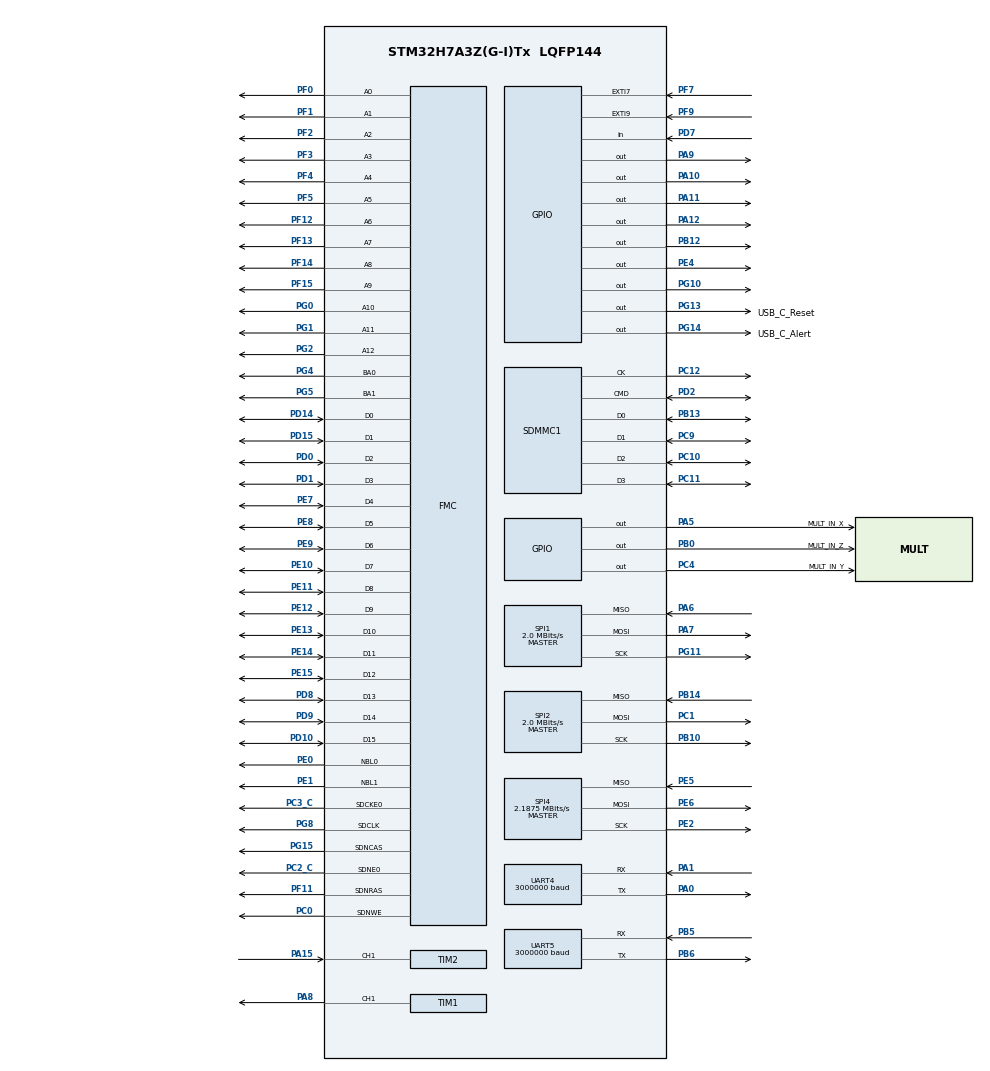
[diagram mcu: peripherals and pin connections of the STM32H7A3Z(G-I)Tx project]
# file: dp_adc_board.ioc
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CORTEX_M7.CPU_DCache=Disabled
CORTEX_M7.CPU_ICache=Disabled
Dma.Request0=SPI4_RX
Dma.Request1=SPI1_RX
Dma.Request2=SPI1_TX
Dma.Request3=SPI2_RX
Dma.Request4=SPI2_TX
Dma.Request5=SPI4_TX
Dma.Request6=UART4_TX
Dma.SPI1_RX.1.Direction=DMA_PERIPH_TO_MEMORY
Dma.SPI1_RX.1.EventEnable=DISABLE
Dma.SPI1_RX.1.FIFOMode=DMA_FIFOMODE_DISABLE
Dma.SPI1_RX.1.Instance=DMA1_Stream0
Dma.SPI1_RX.1.MemDataAlignment=DMA_MDATAALIGN_BYTE
Dma.SPI1_RX.1.MemInc=DMA_MINC_ENABLE
Dma.SPI1_RX.1.Mode=DMA_NORMAL
Dma.SPI1_RX.1.PeriphDataAlignment=DMA_PDATAALIGN_BYTE
Dma.SPI1_RX.1.PeriphInc=DMA_PINC_DISABLE
Dma.SPI1_RX.1.Polarity=HAL_DMAMUX_REQ_GEN_RISING
Dma.SPI1_RX.1.Priority=DMA_PRIORITY_LOW
Dma.SPI1_RX.1.RequestNumber=1
Dma.SPI1_RX.1.SignalID=NONE
Dma.SPI1_RX.1.SyncEnable=DISABLE
Dma.SPI1_RX.1.SyncPolarity=HAL_DMAMUX_SYNC_NO_EVENT
Dma.SPI1_RX.1.SyncRequestNumber=1
Dma.SPI1_RX.1.SyncSignalID=NONE
Dma.SPI1_TX.2.Direction=DMA_MEMORY_TO_PERIPH
Dma.SPI1_TX.2.EventEnable=DISABLE
Dma.SPI1_TX.2.FIFOMode=DMA_FIFOMODE_DISABLE
Dma.SPI1_TX.2.Instance=DMA1_Stream1
Dma.SPI1_TX.2.MemDataAlignment=DMA_MDATAALIGN_BYTE
Dma.SPI1_TX.2.MemInc=DMA_MINC_ENABLE
Dma.SPI1_TX.2.Mode=DMA_NORMAL
Dma.SPI1_TX.2.PeriphDataAlignment=DMA_PDATAALIGN_BYTE
Dma.SPI1_TX.2.PeriphInc=DMA_PINC_DISABLE
Dma.SPI1_TX.2.Polarity=HAL_DMAMUX_REQ_GEN_RISING
Dma.SPI1_TX.2.Priority=DMA_PRIORITY_LOW
Dma.SPI1_TX.2.RequestNumber=1
Dma.SPI1_TX.2.SignalID=NONE
Dma.SPI1_TX.2.SyncEnable=DISABLE
Dma.SPI1_TX.2.SyncPolarity=HAL_DMAMUX_SYNC_NO_EVENT
Dma.SPI1_TX.2.SyncRequestNumber=1
Dma.SPI1_TX.2.SyncSignalID=NONE
Dma.SPI2_RX.3.Direction=DMA_PERIPH_TO_MEMORY
Dma.SPI2_RX.3.EventEnable=DISABLE
Dma.SPI2_RX.3.FIFOMode=DMA_FIFOMODE_DISABLE
Dma.SPI2_RX.3.Instance=DMA1_Stream7
Dma.SPI2_RX.3.MemDataAlignment=DMA_MDATAALIGN_BYTE
Dma.SPI2_RX.3.MemInc=DMA_MINC_ENABLE
Dma.SPI2_RX.3.Mode=DMA_NORMAL
Dma.SPI2_RX.3.PeriphDataAlignment=DMA_PDATAALIGN_BYTE
Dma.SPI2_RX.3.PeriphInc=DMA_PINC_DISABLE
Dma.SPI2_RX.3.Polarity=HAL_DMAMUX_REQ_GEN_RISING
Dma.SPI2_RX.3.Priority=DMA_PRIORITY_LOW
Dma.SPI2_RX.3.RequestNumber=1
Dma.SPI2_RX.3.SignalID=NONE
Dma.SPI2_RX.3.SyncEnable=DISABLE
Dma.SPI2_RX.3.SyncPolarity=HAL_DMAMUX_SYNC_NO_EVENT
Dma.SPI2_RX.3.SyncRequestNumber=1
Dma.SPI2_RX.3.SyncSignalID=NONE
Dma.SPI2_TX.4.Direction=DMA_MEMORY_TO_PERIPH
Dma.SPI2_TX.4.EventEnable=DISABLE
Dma.SPI2_TX.4.FIFOMode=DMA_FIFOMODE_DISABLE
Dma.SPI2_TX.4.Instance=DMA2_Stream0
Dma.SPI2_TX.4.MemDataAlignment=DMA_MDATAALIGN_BYTE
Dma.SPI2_TX.4.MemInc=DMA_MINC_ENABLE
Dma.SPI2_TX.4.Mode=DMA_NORMAL
Dma.SPI2_TX.4.PeriphDataAlignment=DMA_PDATAALIGN_BYTE
Dma.SPI2_TX.4.PeriphInc=DMA_PINC_DISABLE
Dma.SPI2_TX.4.Polarity=HAL_DMAMUX_REQ_GEN_RISING
Dma.SPI2_TX.4.Priority=DMA_PRIORITY_LOW
Dma.SPI2_TX.4.RequestNumber=1
Dma.SPI2_TX.4.SignalID=NONE
Dma.SPI2_TX.4.SyncEnable=DISABLE
Dma.SPI2_TX.4.SyncPolarity=HAL_DMAMUX_SYNC_NO_EVENT
Dma.SPI2_TX.4.SyncRequestNumber=1
Dma.SPI2_TX.4.SyncSignalID=NONE
Dma.SPI4_RX.0.Direction=DMA_PERIPH_TO_MEMORY
Dma.SPI4_RX.0.EventEnable=DISABLE
Dma.SPI4_RX.0.FIFOMode=DMA_FIFOMODE_DISABLE
Dma.SPI4_RX.0.Instance=DMA1_Stream2
Dma.SPI4_RX.0.MemDataAlignment=DMA_MDATAALIGN_BYTE
Dma.SPI4_RX.0.MemInc=DMA_MINC_ENABLE
Dma.SPI4_RX.0.Mode=DMA_NORMAL
Dma.SPI4_RX.0.PeriphDataAlignment=DMA_PDATAALIGN_BYTE
Dma.SPI4_RX.0.PeriphInc=DMA_PINC_DISABLE
Dma.SPI4_RX.0.Polarity=HAL_DMAMUX_REQ_GEN_RISING
Dma.SPI4_RX.0.Priority=DMA_PRIORITY_LOW
Dma.SPI4_RX.0.RequestNumber=1
Dma.SPI4_RX.0.SignalID=NONE
Dma.SPI4_RX.0.SyncEnable=DISABLE
Dma.SPI4_RX.0.SyncPolarity=HAL_DMAMUX_SYNC_NO_EVENT
Dma.SPI4_RX.0.SyncRequestNumber=1
Dma.SPI4_RX.0.SyncSignalID=NONE
Dma.SPI4_TX.5.Direction=DMA_MEMORY_TO_PERIPH
Dma.SPI4_TX.5.EventEnable=DISABLE
Dma.SPI4_TX.5.FIFOMode=DMA_FIFOMODE_DISABLE
Dma.SPI4_TX.5.Instance=DMA1_Stream3
Dma.SPI4_TX.5.MemDataAlignment=DMA_MDATAALIGN_BYTE
Dma.SPI4_TX.5.MemInc=DMA_MINC_ENABLE
Dma.SPI4_TX.5.Mode=DMA_NORMAL
Dma.SPI4_TX.5.PeriphDataAlignment=DMA_PDATAALIGN_BYTE
Dma.SPI4_TX.5.PeriphInc=DMA_PINC_DISABLE
Dma.SPI4_TX.5.Polarity=HAL_DMAMUX_REQ_GEN_RISING
Dma.SPI4_TX.5.Priority=DMA_PRIORITY_LOW
Dma.SPI4_TX.5.RequestNumber=1
Dma.SPI4_TX.5.SignalID=NONE
Dma.SPI4_TX.5.SyncEnable=DISABLE
Dma.SPI4_TX.5.SyncPolarity=HAL_DMAMUX_SYNC_NO_EVENT
Dma.SPI4_TX.5.SyncRequestNumber=1
Dma.SPI4_TX.5.SyncSignalID=NONE
Dma.UART4_TX.6.Direction=DMA_MEMORY_TO_PERIPH
Dma.UART4_TX.6.EventEnable=DISABLE
Dma.UART4_TX.6.FIFOMode=DMA_FIFOMODE_DISABLE
Dma.UART4_TX.6.Instance=DMA1_Stream4
Dma.UART4_TX.6.MemDataAlignment=DMA_MDATAALIGN_BYTE
Dma.UART4_TX.6.MemInc=DMA_MINC_ENABLE
Dma.UART4_TX.6.Mode=DMA_NORMAL
Dma.UART4_TX.6.PeriphDataAlignment=DMA_PDATAALIGN_BYTE
Dma.UART4_TX.6.PeriphInc=DMA_PINC_DISABLE
Dma.UART4_TX.6.Polarity=HAL_DMAMUX_REQ_GEN_RISING
Dma.UART4_TX.6.Priority=DMA_PRIORITY_LOW
Dma.UART4_TX.6.RequestNumber=1
Dma.UART4_TX.6.SignalID=NONE
Dma.UART4_TX.6.SyncEnable=DISABLE
Dma.UART4_TX.6.SyncPolarity=HAL_DMAMUX_SYNC_NO_EVENT
Dma.UART4_TX.6.SyncRequestNumber=1
Dma.UART4_TX.6.SyncSignalID=NONE
FATFS.USE_DMA_CODE_SD=1
FMC.CASLatency1=FMC_SDRAM_CAS_LATENCY_3
FMC.ColumnBitsNumber1=FMC_SDRAM_COLUMN_BITS_NUM_9
FMC.ExitSelfRefreshDelay1=9
FMC.LoadToActiveDelay1=2
FMC.RCDDelay1=3
FMC.RPDelay1=3
FMC.RPDelay2=3
FMC.ReadBurst1=FMC_SDRAM_RBURST_ENABLE
FMC.ReadPipeDelay1=FMC_SDRAM_RPIPE_DELAY_2
FMC.RowCycleDelay1=9
FMC.RowCycleDelay2=9
FMC.SDClockPeriod1=FMC_SDRAM_CLOCK_PERIOD_2
FMC.SelfRefreshTime1=6
FMC.WriteRecoveryTime1=4
Mcu.Family=STM32H7
Mcu.Name=STM32H7A3Z(G-I)Tx
Mcu.Package=LQFP144
NVIC.DMA1_Stream0_IRQn=true\:0\:0\:false\:false\:true\:false\:true\:true
NVIC.DMA1_Stream1_IRQn=true\:0\:0\:false\:false\:true\:false\:true\:true
NVIC.DMA1_Stream2_IRQn=true\:0\:0\:false\:false\:true\:false\:true\:true
NVIC.DMA1_Stream3_IRQn=true\:0\:0\:false\:false\:true\:false\:true\:true
NVIC.DMA1_Stream4_IRQn=true\:0\:0\:false\:false\:true\:false\:true\:true
NVIC.DMA1_Stream7_IRQn=true\:0\:0\:false\:false\:true\:false\:true\:true
NVIC.DMA2_Stream0_IRQn=true\:0\:0\:false\:false\:true\:false\:true\:true
NVIC.PriorityGroup=NVIC_PRIORITYGROUP_4
NVIC.SDMMC1_IRQn=true\:0\:0\:false\:false\:true\:true\:true\:true
NVIC.SPI1_IRQn=true\:0\:0\:false\:false\:true\:true\:true\:true
NVIC.SPI2_IRQn=true\:0\:0\:false\:false\:true\:true\:true\:true
NVIC.SPI4_IRQn=true\:0\:0\:false\:false\:true\:true\:true\:true
NVIC.TIM16_IRQn=true\:0\:0\:false\:false\:true\:true\:true\:true
NVIC.UART4_IRQn=true\:0\:0\:false\:false\:true\:true\:true\:true
NVIC.UART5_IRQn=true\:0\:0\:false\:false\:true\:true\:true\:true
PA0.Mode=Asynchronous
PA0.Signal=UART4_TX
PA1.Mode=Asynchronous
PA1.Signal=UART4_RX
PA10.Signal=GPIO_Output
PA11.Signal=GPIO_Output
PA12.Signal=GPIO_Output
PA13.Mode=Trace_Asynchronous_SW
PA13.Signal=DEBUG_JTMS-SWDIO
PA14.Mode=Trace_Asynchronous_SW
PA14.Signal=DEBUG_JTCK-SWCLK
PA15.Signal=S_TIM2_CH1_ETR
PA5.GPIO_Label=MULT_IN_X
PA5.Signal=GPIO_Output
PA6.Mode=Full_Duplex_Master
PA6.Signal=SPI1_MISO
PA7.Mode=Full_Duplex_Master
PA7.Signal=SPI1_MOSI
PA8.Signal=S_TIM1_CH1
PA9.Signal=GPIO_Output
PB0.GPIO_Label=MULT_IN_Z
PB0.Signal=GPIO_Output
PB10.Mode=Full_Duplex_Master
PB10.Signal=SPI2_SCK
PB12.Signal=GPIO_Output
PB13.Mode=SD_4_bits_Wide_bus
PB13.Signal=SDMMC1_D0
PB14.Mode=Full_Duplex_Master
PB14.Signal=SPI2_MISO
PB3.Mode=Trace_Asynchronous_SW
PB3.Signal=DEBUG_JTDO-SWO
PB5.Mode=Asynchronous
PB5.Signal=UART5_RX
PB6.Mode=Asynchronous
PB6.Signal=UART5_TX
PC0.Signal=FMC_SDNWE
PC1.Mode=Full_Duplex_Master
PC1.Signal=SPI2_MOSI
PC10.Mode=SD_4_bits_Wide_bus
PC10.Signal=SDMMC1_D2
PC11.Mode=SD_4_bits_Wide_bus
PC11.Signal=SDMMC1_D3
PC12.Mode=SD_4_bits_Wide_bus
PC12.Signal=SDMMC1_CK
PC14-OSC32_IN.Mode=LSE-External-Oscillator
PC14-OSC32_IN.Signal=RCC_OSC32_IN
PC15-OSC32_OUT.Mode=LSE-External-Oscillator
PC15-OSC32_OUT.Signal=RCC_OSC32_OUT
PC2_C.Mode=SdramChipSelect1_1
PC2_C.Signal=FMC_SDNE0
PC3_C.Mode=SdramChipSelect1_1
PC3_C.Signal=FMC_SDCKE0
PC4.GPIO_Label=MULT_IN_Y
PC4.Signal=GPIO_Output
PC9.Mode=SD_4_bits_Wide_bus
PC9.Signal=SDMMC1_D1
PD0.Signal=FMC_D2_DA2
PD1.Signal=FMC_D3_DA3
PD10.Signal=FMC_D15_DA15
PD14.Signal=FMC_D0_DA0
PD15.Signal=FMC_D1_DA1
PD2.Mode=SD_4_bits_Wide_bus
PD2.Signal=SDMMC1_CMD
PD7.Signal=GPIO_Input
PD8.Signal=FMC_D13_DA13
PD9.Signal=FMC_D14_DA14
PE0.Signal=FMC_NBL0
PE1.Signal=FMC_NBL1
PE10.Signal=FMC_D7_DA7
PE11.Signal=FMC_D8_DA8
PE12.Signal=FMC_D9_DA9
PE13.Signal=FMC_D10_DA10
PE14.Signal=FMC_D11_DA11
PE15.Signal=FMC_D12_DA12
PE2.Mode=Full_Duplex_Master
PE2.Signal=SPI4_SCK
PE4.Signal=GPIO_Output
PE5.Mode=Full_Duplex_Master
PE5.Signal=SPI4_MISO
PE6.Mode=Full_Duplex_Master
PE6.Signal=SPI4_MOSI
PE7.Signal=FMC_D4_DA4
PE8.Signal=FMC_D5_DA5
PE9.Signal=FMC_D6_DA6
PF0.Signal=FMC_A0
PF1.Signal=FMC_A1
PF11.Signal=FMC_SDNRAS
PF12.Signal=FMC_A6
PF13.Signal=FMC_A7
PF14.Signal=FMC_A8
PF15.Signal=FMC_A9
PF2.Signal=FMC_A2
PF3.Signal=FMC_A3
PF4.Signal=FMC_A4
PF5.Signal=FMC_A5
PF7.GPIO_ModeDefaultEXTI=GPIO_MODE_IT_FALLING
PF7.Signal=GPXTI7
PF9.GPIO_ModeDefaultEXTI=GPIO_MODE_IT_FALLING
PF9.Signal=GPXTI9
PG0.Signal=FMC_A10
PG1.Signal=FMC_A11
PG10.Signal=GPIO_Output
PG11.Mode=Full_Duplex_Master
PG11.Signal=SPI1_SCK
PG13.GPIO_Label=USB_C_Reset
PG13.Signal=GPIO_Output
PG14.GPIO_Label=USB_C_Alert
PG14.Signal=GPIO_Output
PG15.Signal=FMC_SDNCAS
PG2.Signal=FMC_A12
PG4.Signal=FMC_A14_BA0
PG5.Signal=FMC_A15_BA1
PG8.Signal=FMC_SDCLK
PH0-OSC_IN.Mode=HSE-External-Oscillator
PH0-OSC_IN.Signal=RCC_OSC_IN
PH1-OSC_OUT.Mode=HSE-External-Oscillator
PH1-OSC_OUT.Signal=RCC_OSC_OUT
ProjectManager.HeapSize=0x400
ProjectManager.StackSize=0x800
ProjectManager.TargetToolchain=STM32CubeIDE
RCC.ADCFreq_Value=64000000
RCC.APB1Freq_Value=140000000
RCC.APB2Freq_Value=140000000
RCC.APB3Freq_Value=140000000
RCC.APB4Freq_Value=140000000
RCC.CDPPRE=RCC_APB3_DIV2
RCC.CDPPRE1=RCC_APB1_DIV2
RCC.CDPPRE2=RCC_APB2_DIV2
RCC.CortexFreq_Value=280000000
RCC.DIVM1=4
RCC.DIVM2=4
RCC.DIVN1=35
RCC.DIVN2=8
RCC.DIVQ1=1
RCC.FMCCLockSelection=RCC_FMCCLKSOURCE_PLL2
RCC.HCLKFreq_Value=280000000
RCC.HSE_Timout=1000
RCC.HSE_VALUE=24000000
RCC.PLL1_VCO_SEL-AdvancedSettings=RCC_PLL1VCOMEDIUM
RCC.PLL2FRACN=0
RCC.PLL2_VCO_SEL-AdvancedSettings=RCC_PLL2VCOMEDIUM
RCC.PLL3FRACN=0
RCC.PLL3_VCI_Range-AdvancedSettings=RCC_PLL3VCIRANGE_3
RCC.PLLFRACN=0
RCC.PLLSourceVirtual=RCC_PLLSOURCE_HSI
RCC.SDMMC1CLockSelection=RCC_SDMMCCLKSOURCE_PLL2
RCC.SPI123CLockSelection=RCC_SPI123CLKSOURCE_CLKP
RCC.SRDPPRE=RCC_APB4_DIV2
RCC.SYSCLKFreq_VALUE=280000000
RCC.SYSCLKSource=RCC_SYSCLKSOURCE_PLLCLK
RCC.USBFreq_Value=560000000
SDMMC1.ClockDiv=64
SDMMC1.ClockEdge=SDMMC_CLOCK_EDGE_RISING
SH.FMC_A0.0=FMC_A0,13b-sda1
SH.FMC_A1.0=FMC_A1,13b-sda1
SH.FMC_A10.0=FMC_A10,13b-sda1
SH.FMC_A11.0=FMC_A11,13b-sda1
SH.FMC_A12.0=FMC_A12,13b-sda1
SH.FMC_A14_BA0.0=FMC_BA0,FourSdramBanks1
SH.FMC_A15_BA1.0=FMC_BA1,FourSdramBanks1
SH.FMC_A2.0=FMC_A2,13b-sda1
SH.FMC_A3.0=FMC_A3,13b-sda1
SH.FMC_A4.0=FMC_A4,13b-sda1
SH.FMC_A5.0=FMC_A5,13b-sda1
SH.FMC_A6.0=FMC_A6,13b-sda1
SH.FMC_A7.0=FMC_A7,13b-sda1
SH.FMC_A8.0=FMC_A8,13b-sda1
SH.FMC_A9.0=FMC_A9,13b-sda1
SH.FMC_D0_DA0.0=FMC_D0,sd-16b-d1
SH.FMC_D10_DA10.0=FMC_D10,sd-16b-d1
SH.FMC_D11_DA11.0=FMC_D11,sd-16b-d1
SH.FMC_D12_DA12.0=FMC_D12,sd-16b-d1
SH.FMC_D13_DA13.0=FMC_D13,sd-16b-d1
SH.FMC_D14_DA14.0=FMC_D14,sd-16b-d1
SH.FMC_D15_DA15.0=FMC_D15,sd-16b-d1
SH.FMC_D1_DA1.0=FMC_D1,sd-16b-d1
SH.FMC_D2_DA2.0=FMC_D2,sd-16b-d1
SH.FMC_D3_DA3.0=FMC_D3,sd-16b-d1
SH.FMC_D4_DA4.0=FMC_D4,sd-16b-d1
SH.FMC_D5_DA5.0=FMC_D5,sd-16b-d1
SH.FMC_D6_DA6.0=FMC_D6,sd-16b-d1
SH.FMC_D7_DA7.0=FMC_D7,sd-16b-d1
SH.FMC_D8_DA8.0=FMC_D8,sd-16b-d1
SH.FMC_D9_DA9.0=FMC_D9,sd-16b-d1
SH.FMC_NBL0.0=FMC_NBL0,Sd2ByteEnable1
SH.FMC_NBL1.0=FMC_NBL1,Sd2ByteEnable1
SH.FMC_SDCLK.0=FMC_SDCLK,13b-sda1
SH.FMC_SDNCAS.0=FMC_SDNCAS,13b-sda1
SH.FMC_SDNRAS.0=FMC_SDNRAS,13b-sda1
SH.FMC_SDNWE.0=FMC_SDNWE,13b-sda1
SH.S_TIM1_CH1.0=TIM1_CH1,PWM Generation1 CH1
SH.S_TIM2_CH1_ETR.0=TIM2_CH1,Input_Capture1_from_TI1
SPI1.BaudRatePrescaler=SPI_BAUDRATEPRESCALER_32
SPI1.CLKPhase=SPI_PHASE_2EDGE
SPI1.CLKPolarity=SPI_POLARITY_HIGH
SPI1.CalculateBaudRate=2.0 MBits/s
SPI1.DataSize=SPI_DATASIZE_8BIT
SPI1.Direction=SPI_DIRECTION_2LINES
SPI1.Mode=SPI_MODE_MASTER
SPI1.NSSPMode=SPI_NSS_PULSE_DISABLE
SPI1.VirtualType=VM_MASTER
SPI2.BaudRatePrescaler=SPI_BAUDRATEPRESCALER_32
SPI2.CLKPhase=SPI_PHASE_2EDGE
SPI2.CLKPolarity=SPI_POLARITY_HIGH
SPI2.CalculateBaudRate=2.0 MBits/s
SPI2.DataSize=SPI_DATASIZE_8BIT
SPI2.Direction=SPI_DIRECTION_2LINES
SPI2.Mode=SPI_MODE_MASTER
SPI2.NSSPMode=SPI_NSS_PULSE_DISABLE
SPI2.VirtualType=VM_MASTER
SPI4.BaudRatePrescaler=SPI_BAUDRATEPRESCALER_64
SPI4.CLKPhase=SPI_PHASE_2EDGE
SPI4.CLKPolarity=SPI_POLARITY_HIGH
SPI4.CalculateBaudRate=2.1875 MBits/s
SPI4.DataSize=SPI_DATASIZE_8BIT
SPI4.Direction=SPI_DIRECTION_2LINES
SPI4.Mode=SPI_MODE_MASTER
SPI4.NSSPMode=SPI_NSS_PULSE_DISABLE
SPI4.VirtualType=VM_MASTER
TIM1.Channel-PWM\ Generation1\ CH1=TIM_CHANNEL_1
TIM16.Period=10000-1
TIM16.Prescaler=28000-1
TIM2.Channel-Input_Capture1_from_TI1=TIM_CHANNEL_1
TIM2.Prescaler=0
UART4.BaudRate=3000000
UART5.BaudRate=3000000
VP_FATFS_VS_SDIO.Mode=SDIO
VP_TIM16_VS_ClockSourceINT.Mode=Enable_Timer
VP_TIM1_VS_ClockSourceINT.Mode=Internal
VP_TIM2_VS_ClockSourceITR.Mode=TriggerSource_ITR0
VP_TIM2_VS_ControllerModeClock.Mode=Clock Mode
board=custom

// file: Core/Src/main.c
/* USER CODE BEGIN Header */
/**
  ******************************************************************************
  * @file           : main.c
  * @brief          : Main program body
  ******************************************************************************
  * @attention
  *
  * Copyright (c) 2023 STMicroelectronics.
  * All rights reserved.
  *
  * This software is licensed under terms that can be found in the LICENSE file
  * in the root directory of this software component.
  * If no LICENSE file comes with this software, it is provided AS-IS.
  *
  ******************************************************************************
  */
/* USER CODE END Header */
#include "main.h"
#include "fatfs.h"

/* USER CODE BEGIN Includes */
#include <stdio.h>
#include <stdbool.h>
#include "sd_card.h"
#include "fmc_sdram.h"
#include "spi_adc.h"
#include <stdlib.h>
#include <string.h>
/* USER CODE END Includes */

/* USER CODE BEGIN PD */
#define SDRAM_ADD 0xC0000000
#define SDRAM_ADD_INCREMENT 0x27AC40
#define ARRAY_SIZE 12582912
#define SPI_VALUES_TO_CONVERT 5

/* USER CODE END PD */

SD_HandleTypeDef hsd1;

SPI_HandleTypeDef hspi1;
SPI_HandleTypeDef hspi2;
SPI_HandleTypeDef hspi4;
DMA_HandleTypeDef hdma_spi1_rx;
DMA_HandleTypeDef hdma_spi1_tx;
DMA_HandleTypeDef hdma_spi2_rx;
DMA_HandleTypeDef hdma_spi2_tx;
DMA_HandleTypeDef hdma_spi4_rx;
DMA_HandleTypeDef hdma_spi4_tx;

TIM_HandleTypeDef htim1;
TIM_HandleTypeDef htim2;
TIM_HandleTypeDef htim16;

UART_HandleTypeDef huart4;
UART_HandleTypeDef huart5;
DMA_HandleTypeDef hdma_uart4_tx;

SDRAM_HandleTypeDef hsdram1;

/* USER CODE BEGIN PV */
FMC_SDRAM_CommandTypeDef fmc_command;
uint8_t data[1];
uint8_t data2[3];
uint32_t counterSPI1_EXTI = 0;
uint32_t counterSPI2_EXTI = 0;

bool interruptActive = false;

bool flagReset_spi1 = false;
bool flagReset_spi2 = false;
bool flagReset_spi3 = false;
bool sendToSDcard = false;
bool sdCardWriteEnable = false;
bool sdCardInitError = false;
bool sdCardWriteError = false;
bool sdCardOpenFileError = false;

HAL_StatusTypeDef spiStatus[40];
uint8_t pTxData[] = {0x00, 0x00, 0x00, 0x00};
uint8_t adcRawVaues[800]; // 40 x 32bit values
uint32_t tmp_uartCounter = 0;
uint32_t spiValuesBufferCounter = 0;

uint32_t spi1ValuesBufferCounter = 0;
uint32_t spi2ValuesBufferCounter = 0;
uint32_t spi4ValuesBufferCounter = 0;
uint32_t spiCommonBufferCounter = 0;

uint8_t SPS_VALUE_5 = 0x14;
uint8_t SPS_VALUE_20 = 0x11;
uint8_t SPS_VALUE_100 = 0x0E;
uint8_t SPS_VALUE_500 = 0x0B;
uint8_t SPS_VALUE_1000 = 0x0A;

uint8_t spi1Buffer[4] = {0,0,0,0};
uint8_t spi2Buffer[4] = {0,0,0,0};
uint8_t spi4Buffer[4] = {0,0,0,0};

bool spiReadingOngoing;

unsigned long t1 =0;
unsigned long t2 =0;
char fileSpi1Name[] = {'S','P','I','1','.','t','x','t','\0'};
char fileSpi2Name[] = {'S','P','I','2','.','t','x','t','\0'};

uint32_t adcValue_x = 0;
uint32_t adcValue_y = 0;
uint32_t adcValue_z = 0;
uint8_t uartBuffer_x[20];
uint8_t uartBuffer_y[20];
uint8_t uartBuffer_z[20];
int adcLength_x;
int adcLength_x;
int adcLength_x;

uint8_t rxUart4Buffer[1];
uint8_t rxUart5Buffer[1];
uint8_t uartCommand;
bool uartNewCommand = false;

volatile bool enableSPI1Interrupt = false;
bool enableSPI2Interrupt = false;
bool enableSPI4Interrupt = false;

uint32_t spi1ValuesStorage[SDRAM_ADD_INCREMENT] __attribute__((section(".sdram"))) __attribute__((aligned(4)));
uint32_t spi2ValuesStorage[SDRAM_ADD_INCREMENT] __attribute__((section(".sdram"))) __attribute__((aligned(4)));
uint32_t spi4ValuesStorage[SDRAM_ADD_INCREMENT] __attribute__((section(".sdram"))) __attribute__((aligned(4)));

typedef enum {
    red = 0,
    green = 1,
    blue = 2
} colorLED;

char range_x_value = 'H', range_y_value = 'H', range_z_value = 'H';
uint16_t sps = 5;
bool floating_point_values = false, saving_to_sd_card = false;
float gain_x = 0.0f, gain_y = 0.0f, gain_z = 0.0f;
int offset_x = 0, offset_y = 0, offset_z = 0;
bool sending_over_uart = true;

/* USER CODE END PV */

void SystemClock_Config(void);
void PeriphCommonClock_Config(void);
static void MX_GPIO_Init(void);
static void MX_SPI1_Init(void);
static void MX_TIM1_Init(void);
static void MX_UART4_Init(void);
static void MX_FMC_Init(void);
static void MX_SPI2_Init(void);
static void MX_SPI4_Init(void);
static void MX_DMA_Init(void);
static void MX_TIM2_Init(void);
static void MX_SDMMC1_SD_Init(void);
static void MX_TIM16_Init(void);
static void MX_UART5_Init(void);
/* USER CODE BEGIN PFP */
uint32_t findMin(uint32_t a, uint32_t b, uint32_t c);
void setColorLED(colorLED color);
void initialSetupADC(void);
void print_help_uart(void);
/* USER CODE END PFP */

int main(void)
{

  /* MCU Configuration--------------------------------------------------------*/

  /* Reset of all peripherals, Initializes the Flash interface and the Systick. */
  HAL_Init();

  /* Configure the system clock */
  SystemClock_Config();

/* Configure the peripherals common clocks */
  PeriphCommonClock_Config();

  /* USER CODE BEGIN SysInit */
//TODO: need to move DMA init everytime up after GPIO init!!
  /* USER CODE END SysInit */

  /* Initialize all configured peripherals */
  MX_GPIO_Init();
  MX_DMA_Init();
  MX_SPI1_Init();
  MX_TIM1_Init();
  MX_UART4_Init();
  MX_FMC_Init();
  MX_SPI2_Init();
  MX_SPI4_Init();
  MX_TIM2_Init();
  MX_SDMMC1_SD_Init();
  MX_FATFS_Init();
  MX_TIM16_Init();
  MX_UART5_Init();
  /* USER CODE BEGIN 2 */

  // setting up timer for time measuring
  CoreDebug->DEMCR |= CoreDebug_DEMCR_TRCENA_Msk;
  DWT->CYCCNT = 0;
  DWT->CTRL |= DWT_CTRL_CYCCNTENA_Msk;
  HAL_Delay(500);
  /* USER CODE END 2 */

  /* Infinite loop */
  /* USER CODE BEGIN WHILE */
  SDRAM_Startup_Sequence(&hsdram1, &fmc_command);
  sdCardInitError = sd_card_init();
  HAL_Delay(100);

  HAL_NVIC_SetPriority(EXTI9_5_IRQn, 4, 4);
  HAL_NVIC_SetPriority(EXTI15_10_IRQn, 1, 1);
  HAL_NVIC_DisableIRQ(EXTI9_5_IRQn);
  HAL_NVIC_DisableIRQ(EXTI15_10_IRQn);

  // uart4 and uart5 IT enable
  HAL_UART_Receive_IT (&huart4, rxUart4Buffer, 1);
  HAL_UART_Receive_IT (&huart5, rxUart5Buffer, 1);

  // LED timer enable
  HAL_TIM_Base_Start_IT(&htim16);

  if (sdCardInitError == true){
    setColorLED(red);
  }else{
    setColorLED(blue);
    readConfigFile("config.txt");
  }

  spi1_soft_reset();
  spi2_soft_reset();
  spi4_soft_reset();
  spi1_adc_init(SPS_VALUE_5);
  spi2_adc_init(SPS_VALUE_5);
  spi4_adc_init(SPS_VALUE_5);

  //initial setup:
  initialSetupADC();
  HAL_Delay(500);

  __HAL_GPIO_EXTI_CLEAR_IT(GPIO_PIN_5);
  __HAL_GPIO_EXTI_CLEAR_IT(GPIO_PIN_6);
  __HAL_GPIO_EXTI_CLEAR_IT(GPIO_PIN_14);
  HAL_NVIC_EnableIRQ(EXTI9_5_IRQn);
  HAL_NVIC_EnableIRQ(EXTI15_10_IRQn);

  //run all before main loop
  run_all_adc();

  char stringBufferValues[39];

  floating_point_values = true;
    while (1){
      if(spiCommonBufferCounter < findMin(spi1ValuesBufferCounter,spi2ValuesBufferCounter,spi4ValuesBufferCounter)){
        if (floating_point_values == true){
          getStringFromValuesFloat(spi1ValuesStorage[spiCommonBufferCounter],spi2ValuesStorage[spiCommonBufferCounter],spi4ValuesStorage[spiCommonBufferCounter],stringBufferValues, range_x_value, range_y_value, range_z_value);
          if (sending_over_uart ==  true){
            HAL_UART_Transmit(&huart4, stringBufferValues, 33,100);
            HAL_UART_Transmit(&huart5, stringBufferValues, 33,100);
          }
        }else{
          getStringFromValues(spi1ValuesStorage[spiCommonBufferCounter],spi2ValuesStorage[spiCommonBufferCounter],spi4ValuesStorage[spiCommonBufferCounter],stringBufferValues);
          if (sending_over_uart == true){
            HAL_UART_Transmit(&huart4, stringBufferValues, 33,100);
            HAL_UART_Transmit(&huart5, stringBufferValues, 33,100);
          }
        }

        if((sdCardWriteEnable == true) && (sdCardInitError == false) && (sdCardOpenFileError == false)){
          sdCardWriteError = sd_card_write_to_opened_file(stringBufferValues);
          if (sdCardWriteError == true){
            setColorLED(red);
          }else{
            setColorLED(green);
          }
        }
      spiCommonBufferCounter++;
      }

      if (uartNewCommand == true){
        switch (uartCommand) {
          case 'a': // multiplexer X -> 0
            HAL_GPIO_WritePin(GPIOA, GPIO_PIN_5, GPIO_PIN_RESET);
            break;
          case 'b': // multiplexer X -> 1
            HAL_GPIO_WritePin(GPIOA, GPIO_PIN_5, GPIO_PIN_SET);
            break;

          case 'c': // multiplexer Y -> 0
            HAL_GPIO_WritePin(GPIOC, GPIO_PIN_4, GPIO_PIN_RESET);
            break;

          case 'd': // multiplexer Y -> 1
            HAL_GPIO_WritePin(GPIOC, GPIO_PIN_4, GPIO_PIN_SET);
            break;

          case 'e': // multiplexer Z -> 0
            HAL_GPIO_WritePin(GPIOB, GPIO_PIN_0, GPIO_PIN_RESET);
            break;

          case 'f': // multiplexer Z -> 1
            HAL_GPIO_WritePin(GPIOB, GPIO_PIN_0, GPIO_PIN_SET);
            break;

          case 'p':
            floating_point_values = true;
            break;

          case 'r':
            floating_point_values = false;
            break;

          case 's':
            sending_over_uart = true;
            break;

          case 't':
            sending_over_uart = false;
            break;

          case 'h':
          case '?':
            sending_over_uart = false;
            print_help_uart();
            break;

         // Numbers reserved for SPS values
          case '0':
            //set SPS to 5
            setNewSPStoAllADCs(SPS_VALUE_5);
            break;
          case '1':
            //set SPS to 20
            setNewSPStoAllADCs(SPS_VALUE_20);
            break;
          case '2':
            //set SPS to 100
            setNewSPStoAllADCs(SPS_VALUE_100);
            break;
          case '3':
            //set SPS to 500
            setNewSPStoAllADCs(SPS_VALUE_500);
            break;
          case '4':
            //set SPS to 1000
            setNewSPStoAllADCs(SPS_VALUE_1000);
            break;
          default:
            break;
        }
        uartNewCommand = false;
      }
    /* USER CODE END WHILE */

    }
}

void SystemClock_Config(void)
{
  RCC_OscInitTypeDef RCC_OscInitStruct = {0};
  RCC_ClkInitTypeDef RCC_ClkInitStruct = {0};

  /*AXI clock gating */
  RCC->CKGAENR = 0xFFFFFFFF;

  /** Supply configuration update enable
  */
  HAL_PWREx_ConfigSupply(PWR_LDO_SUPPLY);

  /** Configure the main internal regulator output voltage
  */
  __HAL_PWR_VOLTAGESCALING_CONFIG(PWR_REGULATOR_VOLTAGE_SCALE0);

  while(!__HAL_PWR_GET_FLAG(PWR_FLAG_VOSRDY)) {}

  /** Macro to configure the PLL clock source
  */
  __HAL_RCC_PLL_PLLSOURCE_CONFIG(RCC_PLLSOURCE_HSI);

  /** Initializes the RCC Oscillators according to the specified parameters
  * in the RCC_OscInitTypeDef structure.
  */
  RCC_OscInitStruct.OscillatorType = RCC_OSCILLATORTYPE_HSI;
  RCC_OscInitStruct.HSIState = RCC_HSI_DIV1;
  RCC_OscInitStruct.HSICalibrationValue = RCC_HSICALIBRATION_DEFAULT;
  RCC_OscInitStruct.PLL.PLLState = RCC_PLL_ON;
  RCC_OscInitStruct.PLL.PLLSource = RCC_PLLSOURCE_HSI;
  RCC_OscInitStruct.PLL.PLLM = 4;
  RCC_OscInitStruct.PLL.PLLN = 35;
  RCC_OscInitStruct.PLL.PLLP = 2;
  RCC_OscInitStruct.PLL.PLLQ = 1;
  RCC_OscInitStruct.PLL.PLLR = 2;
  RCC_OscInitStruct.PLL.PLLRGE = RCC_PLL1VCIRANGE_3;
  RCC_OscInitStruct.PLL.PLLVCOSEL = RCC_PLL1VCOWIDE;
  RCC_OscInitStruct.PLL.PLLFRACN = 0;
  if (HAL_RCC_OscConfig(&RCC_OscInitStruct) != HAL_OK)
  {
    Error_Handler();
  }

  /** Initializes the CPU, AHB and APB buses clocks
  */
  RCC_ClkInitStruct.ClockType = RCC_CLOCKTYPE_HCLK|RCC_CLOCKTYPE_SYSCLK
                              |RCC_CLOCKTYPE_PCLK1|RCC_CLOCKTYPE_PCLK2
                              |RCC_CLOCKTYPE_D3PCLK1|RCC_CLOCKTYPE_D1PCLK1;
  RCC_ClkInitStruct.SYSCLKSource = RCC_SYSCLKSOURCE_PLLCLK;
  RCC_ClkInitStruct.SYSCLKDivider = RCC_SYSCLK_DIV1;
  RCC_ClkInitStruct.AHBCLKDivider = RCC_HCLK_DIV1;
  RCC_ClkInitStruct.APB3CLKDivider = RCC_APB3_DIV2;
  RCC_ClkInitStruct.APB1CLKDivider = RCC_APB1_DIV2;
  RCC_ClkInitStruct.APB2CLKDivider = RCC_APB2_DIV2;
  RCC_ClkInitStruct.APB4CLKDivider = RCC_APB4_DIV2;

  if (HAL_RCC_ClockConfig(&RCC_ClkInitStruct, FLASH_LATENCY_7) != HAL_OK)
  {
    Error_Handler();
  }
}

void PeriphCommonClock_Config(void)
{
  RCC_PeriphCLKInitTypeDef PeriphClkInitStruct = {0};

  /** Initializes the peripherals clock
  */
  PeriphClkInitStruct.PeriphClockSelection = RCC_PERIPHCLK_FMC|RCC_PERIPHCLK_SDMMC
                              |RCC_PERIPHCLK_CKPER;
  PeriphClkInitStruct.PLL2.PLL2M = 4;
  PeriphClkInitStruct.PLL2.PLL2N = 8;
  PeriphClkInitStruct.PLL2.PLL2P = 2;
  PeriphClkInitStruct.PLL2.PLL2Q = 2;
  PeriphClkInitStruct.PLL2.PLL2R = 2;
  PeriphClkInitStruct.PLL2.PLL2RGE = RCC_PLL2VCIRANGE_3;
  PeriphClkInitStruct.PLL2.PLL2VCOSEL = RCC_PLL2VCOWIDE;
  PeriphClkInitStruct.PLL2.PLL2FRACN = 0;
  PeriphClkInitStruct.FmcClockSelection = RCC_FMCCLKSOURCE_PLL2;
  PeriphClkInitStruct.SdmmcClockSelection = RCC_SDMMCCLKSOURCE_PLL2;
  PeriphClkInitStruct.CkperClockSelection = RCC_CLKPSOURCE_HSI;
  if (HAL_RCCEx_PeriphCLKConfig(&PeriphClkInitStruct) != HAL_OK)
  {
    Error_Handler();
  }
}

static void MX_SDMMC1_SD_Init(void)
{

  hsd1.Instance = SDMMC1;
  hsd1.Init.ClockEdge = SDMMC_CLOCK_EDGE_RISING;
  hsd1.Init.ClockPowerSave = SDMMC_CLOCK_POWER_SAVE_DISABLE;
  hsd1.Init.BusWide = SDMMC_BUS_WIDE_4B;
  hsd1.Init.HardwareFlowControl = SDMMC_HARDWARE_FLOW_CONTROL_DISABLE;
  hsd1.Init.ClockDiv = 64;

}

static void MX_SPI1_Init(void)
{

  /* SPI1 parameter configuration*/
  hspi1.Instance = SPI1;
  hspi1.Init.Mode = SPI_MODE_MASTER;
  hspi1.Init.Direction = SPI_DIRECTION_2LINES;
  hspi1.Init.DataSize = SPI_DATASIZE_8BIT;
  hspi1.Init.CLKPolarity = SPI_POLARITY_HIGH;
  hspi1.Init.CLKPhase = SPI_PHASE_2EDGE;
  hspi1.Init.NSS = SPI_NSS_SOFT;
  hspi1.Init.BaudRatePrescaler = SPI_BAUDRATEPRESCALER_32;
  hspi1.Init.FirstBit = SPI_FIRSTBIT_MSB;
  hspi1.Init.TIMode = SPI_TIMODE_DISABLE;
  hspi1.Init.CRCCalculation = SPI_CRCCALCULATION_DISABLE;
  hspi1.Init.CRCPolynomial = 0x0;
  hspi1.Init.NSSPMode = SPI_NSS_PULSE_DISABLE;
  hspi1.Init.NSSPolarity = SPI_NSS_POLARITY_LOW;
  hspi1.Init.FifoThreshold = SPI_FIFO_THRESHOLD_01DATA;
  hspi1.Init.TxCRCInitializationPattern = SPI_CRC_INITIALIZATION_ALL_ZERO_PATTERN;
  hspi1.Init.RxCRCInitializationPattern = SPI_CRC_INITIALIZATION_ALL_ZERO_PATTERN;
  hspi1.Init.MasterSSIdleness = SPI_MASTER_SS_IDLENESS_00CYCLE;
  hspi1.Init.MasterInterDataIdleness = SPI_MASTER_INTERDATA_IDLENESS_00CYCLE;
  hspi1.Init.MasterReceiverAutoSusp = SPI_MASTER_RX_AUTOSUSP_DISABLE;
  hspi1.Init.MasterKeepIOState = SPI_MASTER_KEEP_IO_STATE_DISABLE;
  hspi1.Init.IOSwap = SPI_IO_SWAP_DISABLE;
  if (HAL_SPI_Init(&hspi1) != HAL_OK)
  {
    Error_Handler();
  }

}

static void MX_SPI2_Init(void)
{

  /* SPI2 parameter configuration*/
  hspi2.Instance = SPI2;
  hspi2.Init.Mode = SPI_MODE_MASTER;
  hspi2.Init.Direction = SPI_DIRECTION_2LINES;
  hspi2.Init.DataSize = SPI_DATASIZE_8BIT;
  hspi2.Init.CLKPolarity = SPI_POLARITY_HIGH;
  hspi2.Init.CLKPhase = SPI_PHASE_2EDGE;
  hspi2.Init.NSS = SPI_NSS_SOFT;
  hspi2.Init.BaudRatePrescaler = SPI_BAUDRATEPRESCALER_32;
  hspi2.Init.FirstBit = SPI_FIRSTBIT_MSB;
  hspi2.Init.TIMode = SPI_TIMODE_DISABLE;
  hspi2.Init.CRCCalculation = SPI_CRCCALCULATION_DISABLE;
  hspi2.Init.CRCPolynomial = 0x0;
  hspi2.Init.NSSPMode = SPI_NSS_PULSE_DISABLE;
  hspi2.Init.NSSPolarity = SPI_NSS_POLARITY_LOW;
  hspi2.Init.FifoThreshold = SPI_FIFO_THRESHOLD_01DATA;
  hspi2.Init.TxCRCInitializationPattern = SPI_CRC_INITIALIZATION_ALL_ZERO_PATTERN;
  hspi2.Init.RxCRCInitializationPattern = SPI_CRC_INITIALIZATION_ALL_ZERO_PATTERN;
  hspi2.Init.MasterSSIdleness = SPI_MASTER_SS_IDLENESS_00CYCLE;
  hspi2.Init.MasterInterDataIdleness = SPI_MASTER_INTERDATA_IDLENESS_00CYCLE;
  hspi2.Init.MasterReceiverAutoSusp = SPI_MASTER_RX_AUTOSUSP_DISABLE;
  hspi2.Init.MasterKeepIOState = SPI_MASTER_KEEP_IO_STATE_DISABLE;
  hspi2.Init.IOSwap = SPI_IO_SWAP_DISABLE;
  if (HAL_SPI_Init(&hspi2) != HAL_OK)
  {
    Error_Handler();
  }

}

static void MX_SPI4_Init(void)
{

  /* SPI4 parameter configuration*/
  hspi4.Instance = SPI4;
  hspi4.Init.Mode = SPI_MODE_MASTER;
  hspi4.Init.Direction = SPI_DIRECTION_2LINES;
  hspi4.Init.DataSize = SPI_DATASIZE_8BIT;
  hspi4.Init.CLKPolarity = SPI_POLARITY_HIGH;
  hspi4.Init.CLKPhase = SPI_PHASE_2EDGE;
  hspi4.Init.NSS = SPI_NSS_SOFT;
  hspi4.Init.BaudRatePrescaler = SPI_BAUDRATEPRESCALER_64;
  hspi4.Init.FirstBit = SPI_FIRSTBIT_MSB;
  hspi4.Init.TIMode = SPI_TIMODE_DISABLE;
  hspi4.Init.CRCCalculation = SPI_CRCCALCULATION_DISABLE;
  hspi4.Init.CRCPolynomial = 0x0;
  hspi4.Init.NSSPMode = SPI_NSS_PULSE_DISABLE;
  hspi4.Init.NSSPolarity = SPI_NSS_POLARITY_LOW;
  hspi4.Init.FifoThreshold = SPI_FIFO_THRESHOLD_01DATA;
  hspi4.Init.TxCRCInitializationPattern = SPI_CRC_INITIALIZATION_ALL_ZERO_PATTERN;
  hspi4.Init.RxCRCInitializationPattern = SPI_CRC_INITIALIZATION_ALL_ZERO_PATTERN;
  hspi4.Init.MasterSSIdleness = SPI_MASTER_SS_IDLENESS_00CYCLE;
  hspi4.Init.MasterInterDataIdleness = SPI_MASTER_INTERDATA_IDLENESS_00CYCLE;
  hspi4.Init.MasterReceiverAutoSusp = SPI_MASTER_RX_AUTOSUSP_DISABLE;
  hspi4.Init.MasterKeepIOState = SPI_MASTER_KEEP_IO_STATE_DISABLE;
  hspi4.Init.IOSwap = SPI_IO_SWAP_DISABLE;
  if (HAL_SPI_Init(&hspi4) != HAL_OK)
  {
    Error_Handler();
  }

}

static void MX_TIM1_Init(void)
{

  TIM_ClockConfigTypeDef sClockSourceConfig = {0};
  TIM_MasterConfigTypeDef sMasterConfig = {0};
  TIM_OC_InitTypeDef sConfigOC = {0};
  TIM_BreakDeadTimeConfigTypeDef sBreakDeadTimeConfig = {0};

  htim1.Instance = TIM1;
  htim1.Init.Prescaler = 0;
  htim1.Init.CounterMode = TIM_COUNTERMODE_UP;
  htim1.Init.Period = 65535;
  htim1.Init.ClockDivision = TIM_CLOCKDIVISION_DIV1;
  htim1.Init.RepetitionCounter = 0;
  htim1.Init.AutoReloadPreload = TIM_AUTORELOAD_PRELOAD_DISABLE;
  if (HAL_TIM_Base_Init(&htim1) != HAL_OK)
  {
    Error_Handler();
  }
  sClockSourceConfig.ClockSource = TIM_CLOCKSOURCE_INTERNAL;
  if (HAL_TIM_ConfigClockSource(&htim1, &sClockSourceConfig) != HAL_OK)
  {
    Error_Handler();
  }
  if (HAL_TIM_PWM_Init(&htim1) != HAL_OK)
  {
    Error_Handler();
  }
  sMasterConfig.MasterOutputTrigger = TIM_TRGO_RESET;
  sMasterConfig.MasterOutputTrigger2 = TIM_TRGO2_RESET;
  sMasterConfig.MasterSlaveMode = TIM_MASTERSLAVEMODE_DISABLE;
  if (HAL_TIMEx_MasterConfigSynchronization(&htim1, &sMasterConfig) != HAL_OK)
  {
    Error_Handler();
  }
  sConfigOC.OCMode = TIM_OCMODE_PWM1;
  sConfigOC.Pulse = 0;
  sConfigOC.OCPolarity = TIM_OCPOLARITY_HIGH;
  sConfigOC.OCNPolarity = TIM_OCNPOLARITY_HIGH;
  sConfigOC.OCFastMode = TIM_OCFAST_DISABLE;
  sConfigOC.OCIdleState = TIM_OCIDLESTATE_RESET;
  sConfigOC.OCNIdleState = TIM_OCNIDLESTATE_RESET;
  if (HAL_TIM_PWM_ConfigChannel(&htim1, &sConfigOC, TIM_CHANNEL_1) != HAL_OK)
  {
    Error_Handler();
  }
  sBreakDeadTimeConfig.OffStateRunMode = TIM_OSSR_DISABLE;
  sBreakDeadTimeConfig.OffStateIDLEMode = TIM_OSSI_DISABLE;
  sBreakDeadTimeConfig.LockLevel = TIM_LOCKLEVEL_OFF;
  sBreakDeadTimeConfig.DeadTime = 0;
  sBreakDeadTimeConfig.BreakState = TIM_BREAK_DISABLE;
  sBreakDeadTimeConfig.BreakPolarity = TIM_BREAKPOLARITY_HIGH;
  sBreakDeadTimeConfig.BreakFilter = 0;
  sBreakDeadTimeConfig.Break2State = TIM_BREAK2_DISABLE;
  sBreakDeadTimeConfig.Break2Polarity = TIM_BREAK2POLARITY_HIGH;
  sBreakDeadTimeConfig.Break2Filter = 0;
  sBreakDeadTimeConfig.AutomaticOutput = TIM_AUTOMATICOUTPUT_DISABLE;
  if (HAL_TIMEx_ConfigBreakDeadTime(&htim1, &sBreakDeadTimeConfig) != HAL_OK)
  {
    Error_Handler();
  }
  HAL_TIM_MspPostInit(&htim1);

}

static void MX_TIM2_Init(void)
{

  TIM_SlaveConfigTypeDef sSlaveConfig = {0};
  TIM_MasterConfigTypeDef sMasterConfig = {0};
  TIM_IC_InitTypeDef sConfigIC = {0};

  htim2.Instance = TIM2;
  htim2.Init.Prescaler = 0;
  htim2.Init.CounterMode = TIM_COUNTERMODE_UP;
  htim2.Init.Period = 4294967295;
  htim2.Init.ClockDivision = TIM_CLOCKDIVISION_DIV1;
  htim2.Init.AutoReloadPreload = TIM_AUTORELOAD_PRELOAD_DISABLE;
  if (HAL_TIM_Base_Init(&htim2) != HAL_OK)
  {
    Error_Handler();
  }
  if (HAL_TIM_IC_Init(&htim2) != HAL_OK)
  {
    Error_Handler();
  }
  sSlaveConfig.SlaveMode = TIM_SLAVEMODE_EXTERNAL1;
  sSlaveConfig.InputTrigger = TIM_TS_ITR0;
  if (HAL_TIM_SlaveConfigSynchro(&htim2, &sSlaveConfig) != HAL_OK)
  {
    Error_Handler();
  }
  sMasterConfig.MasterOutputTrigger = TIM_TRGO_RESET;
  sMasterConfig.MasterSlaveMode = TIM_MASTERSLAVEMODE_DISABLE;
  if (HAL_TIMEx_MasterConfigSynchronization(&htim2, &sMasterConfig) != HAL_OK)
  {
    Error_Handler();
  }
  sConfigIC.ICPolarity = TIM_INPUTCHANNELPOLARITY_RISING;
  sConfigIC.ICSelection = TIM_ICSELECTION_DIRECTTI;
  sConfigIC.ICPrescaler = TIM_ICPSC_DIV1;
  sConfigIC.ICFilter = 0;
  if (HAL_TIM_IC_ConfigChannel(&htim2, &sConfigIC, TIM_CHANNEL_1) != HAL_OK)
  {
    Error_Handler();
  }

}

static void MX_TIM16_Init(void)
{

  htim16.Instance = TIM16;
  htim16.Init.Prescaler = 28000-1;
  htim16.Init.CounterMode = TIM_COUNTERMODE_UP;
  htim16.Init.Period = 10000-1;
  htim16.Init.ClockDivision = TIM_CLOCKDIVISION_DIV1;
  htim16.Init.RepetitionCounter = 0;
  htim16.Init.AutoReloadPreload = TIM_AUTORELOAD_PRELOAD_DISABLE;
  if (HAL_TIM_Base_Init(&htim16) != HAL_OK)
  {
    Error_Handler();
  }

}

static void MX_UART4_Init(void)
{

  huart4.Instance = UART4;
  huart4.Init.BaudRate = 3000000;
  huart4.Init.WordLength = UART_WORDLENGTH_8B;
  huart4.Init.StopBits = UART_STOPBITS_1;
  huart4.Init.Parity = UART_PARITY_NONE;
  huart4.Init.Mode = UART_MODE_TX_RX;
  huart4.Init.HwFlowCtl = UART_HWCONTROL_NONE;
  huart4.Init.OverSampling = UART_OVERSAMPLING_16;
  huart4.Init.OneBitSampling = UART_ONE_BIT_SAMPLE_DISABLE;
  huart4.Init.ClockPrescaler = UART_PRESCALER_DIV1;
  huart4.AdvancedInit.AdvFeatureInit = UART_ADVFEATURE_NO_INIT;
  if (HAL_UART_Init(&huart4) != HAL_OK)
  {
    Error_Handler();
  }
  if (HAL_UARTEx_SetTxFifoThreshold(&huart4, UART_TXFIFO_THRESHOLD_1_8) != HAL_OK)
  {
    Error_Handler();
  }
  if (HAL_UARTEx_SetRxFifoThreshold(&huart4, UART_RXFIFO_THRESHOLD_1_8) != HAL_OK)
  {
    Error_Handler();
  }
  if (HAL_UARTEx_DisableFifoMode(&huart4) != HAL_OK)
  {
    Error_Handler();
  }

}

static void MX_UART5_Init(void)
{

  huart5.Instance = UART5;
  huart5.Init.BaudRate = 3000000;
  huart5.Init.WordLength = UART_WORDLENGTH_8B;
  huart5.Init.StopBits = UART_STOPBITS_1;
  huart5.Init.Parity = UART_PARITY_NONE;
  huart5.Init.Mode = UART_MODE_TX_RX;
  huart5.Init.HwFlowCtl = UART_HWCONTROL_NONE;
  huart5.Init.OverSampling = UART_OVERSAMPLING_16;
  huart5.Init.OneBitSampling = UART_ONE_BIT_SAMPLE_DISABLE;
  huart5.Init.ClockPrescaler = UART_PRESCALER_DIV1;
  huart5.AdvancedInit.AdvFeatureInit = UART_ADVFEATURE_NO_INIT;
  if (HAL_UART_Init(&huart5) != HAL_OK)
  {
    Error_Handler();
  }
  if (HAL_UARTEx_SetTxFifoThreshold(&huart5, UART_TXFIFO_THRESHOLD_1_8) != HAL_OK)
  {
    Error_Handler();
  }
  if (HAL_UARTEx_SetRxFifoThreshold(&huart5, UART_RXFIFO_THRESHOLD_1_8) != HAL_OK)
  {
    Error_Handler();
  }
  if (HAL_UARTEx_DisableFifoMode(&huart5) != HAL_OK)
  {
    Error_Handler();
  }

}

static void MX_DMA_Init(void)
{

  /* DMA controller clock enable */
  __HAL_RCC_DMA1_CLK_ENABLE();
  __HAL_RCC_DMA2_CLK_ENABLE();

  /* DMA interrupt init */
  /* DMA1_Stream0_IRQn interrupt configuration */
  HAL_NVIC_SetPriority(DMA1_Stream0_IRQn, 0, 0);
  HAL_NVIC_EnableIRQ(DMA1_Stream0_IRQn);
  /* DMA1_Stream1_IRQn interrupt configuration */
  HAL_NVIC_SetPriority(DMA1_Stream1_IRQn, 0, 0);
  HAL_NVIC_EnableIRQ(DMA1_Stream1_IRQn);
  /* DMA1_Stream2_IRQn interrupt configuration */
  HAL_NVIC_SetPriority(DMA1_Stream2_IRQn, 0, 0);
  HAL_NVIC_EnableIRQ(DMA1_Stream2_IRQn);
  /* DMA1_Stream3_IRQn interrupt configuration */
  HAL_NVIC_SetPriority(DMA1_Stream3_IRQn, 0, 0);
  HAL_NVIC_EnableIRQ(DMA1_Stream3_IRQn);
  /* DMA1_Stream4_IRQn interrupt configuration */
  HAL_NVIC_SetPriority(DMA1_Stream4_IRQn, 0, 0);
  HAL_NVIC_EnableIRQ(DMA1_Stream4_IRQn);
  /* DMA1_Stream7_IRQn interrupt configuration */
  HAL_NVIC_SetPriority(DMA1_Stream7_IRQn, 0, 0);
  HAL_NVIC_EnableIRQ(DMA1_Stream7_IRQn);
  /* DMA2_Stream0_IRQn interrupt configuration */
  HAL_NVIC_SetPriority(DMA2_Stream0_IRQn, 0, 0);
  HAL_NVIC_EnableIRQ(DMA2_Stream0_IRQn);

}

/* FMC initialization function */
static void MX_FMC_Init(void)
{

  FMC_SDRAM_TimingTypeDef SdramTiming = {0};

  /** Perform the SDRAM1 memory initialization sequence
  */
  hsdram1.Instance = FMC_SDRAM_DEVICE;
  /* hsdram1.Init */
  hsdram1.Init.SDBank = FMC_SDRAM_BANK1;
  hsdram1.Init.ColumnBitsNumber = FMC_SDRAM_COLUMN_BITS_NUM_9;
  hsdram1.Init.RowBitsNumber = FMC_SDRAM_ROW_BITS_NUM_13;
  hsdram1.Init.MemoryDataWidth = FMC_SDRAM_MEM_BUS_WIDTH_16;
  hsdram1.Init.InternalBankNumber = FMC_SDRAM_INTERN_BANKS_NUM_4;
  hsdram1.Init.CASLatency = FMC_SDRAM_CAS_LATENCY_3;
  hsdram1.Init.WriteProtection = FMC_SDRAM_WRITE_PROTECTION_DISABLE;
  hsdram1.Init.SDClockPeriod = FMC_SDRAM_CLOCK_PERIOD_2;
  hsdram1.Init.ReadBurst = FMC_SDRAM_RBURST_ENABLE;
  hsdram1.Init.ReadPipeDelay = FMC_SDRAM_RPIPE_DELAY_2;
  /* SdramTiming */
  SdramTiming.LoadToActiveDelay = 2;
  SdramTiming.ExitSelfRefreshDelay = 9;
  SdramTiming.SelfRefreshTime = 6;
  SdramTiming.RowCycleDelay = 9;
  SdramTiming.WriteRecoveryTime = 4;
  SdramTiming.RPDelay = 3;
  SdramTiming.RCDDelay = 3;

  if (HAL_SDRAM_Init(&hsdram1, &SdramTiming) != HAL_OK)
  {
    Error_Handler( );
  }

}

static void MX_GPIO_Init(void)
{
  GPIO_InitTypeDef GPIO_InitStruct = {0};

  /* GPIO Ports Clock Enable */
  __HAL_RCC_GPIOE_CLK_ENABLE();
  __HAL_RCC_GPIOC_CLK_ENABLE();
  __HAL_RCC_GPIOF_CLK_ENABLE();
  __HAL_RCC_GPIOH_CLK_ENABLE();
  __HAL_RCC_GPIOA_CLK_ENABLE();
  __HAL_RCC_GPIOB_CLK_ENABLE();
  __HAL_RCC_GPIOG_CLK_ENABLE();
  __HAL_RCC_GPIOD_CLK_ENABLE();

  /*Configure GPIO pin Output Level */
  HAL_GPIO_WritePin(GPIOE, GPIO_PIN_4, GPIO_PIN_RESET);

  /*Configure GPIO pin Output Level */
  HAL_GPIO_WritePin(GPIOA, MULT_IN_X_Pin|GPIO_PIN_9|GPIO_PIN_10|GPIO_PIN_11
                          |GPIO_PIN_12, GPIO_PIN_RESET);

  /*Configure GPIO pin Output Level */
  HAL_GPIO_WritePin(MULT_IN_Y_GPIO_Port, MULT_IN_Y_Pin, GPIO_PIN_RESET);

  /*Configure GPIO pin Output Level */
  HAL_GPIO_WritePin(GPIOB, MULT_IN_Z_Pin|GPIO_PIN_12, GPIO_PIN_RESET);

  /*Configure GPIO pin Output Level */
  HAL_GPIO_WritePin(GPIOG, GPIO_PIN_10|USB_C_Reset_Pin|USB_C_Alert_Pin, GPIO_PIN_RESET);

  /*Configure GPIO pin : PE4 */
  GPIO_InitStruct.Pin = GPIO_PIN_4;
  GPIO_InitStruct.Mode = GPIO_MODE_OUTPUT_PP;
  GPIO_InitStruct.Pull = GPIO_NOPULL;
  GPIO_InitStruct.Speed = GPIO_SPEED_FREQ_LOW;
  HAL_GPIO_Init(GPIOE, &GPIO_InitStruct);

  /*Configure GPIO pins : PF7 PF9 */
  GPIO_InitStruct.Pin = GPIO_PIN_7|GPIO_PIN_9;
  GPIO_InitStruct.Mode = GPIO_MODE_IT_FALLING;
  GPIO_InitStruct.Pull = GPIO_NOPULL;
  HAL_GPIO_Init(GPIOF, &GPIO_InitStruct);

  /*Configure GPIO pins : MULT_IN_X_Pin PA9 PA10 PA11
                           PA12 */
  GPIO_InitStruct.Pin = MULT_IN_X_Pin|GPIO_PIN_9|GPIO_PIN_10|GPIO_PIN_11
                          |GPIO_PIN_12;
  GPIO_InitStruct.Mode = GPIO_MODE_OUTPUT_PP;
  GPIO_InitStruct.Pull = GPIO_NOPULL;
  GPIO_InitStruct.Speed = GPIO_SPEED_FREQ_LOW;
  HAL_GPIO_Init(GPIOA, &GPIO_InitStruct);

  /*Configure GPIO pin : MULT_IN_Y_Pin */
  GPIO_InitStruct.Pin = MULT_IN_Y_Pin;
  GPIO_InitStruct.Mode = GPIO_MODE_OUTPUT_PP;
  GPIO_InitStruct.Pull = GPIO_NOPULL;
  GPIO_InitStruct.Speed = GPIO_SPEED_FREQ_LOW;
  HAL_GPIO_Init(MULT_IN_Y_GPIO_Port, &GPIO_InitStruct);

  /*Configure GPIO pins : MULT_IN_Z_Pin PB12 */
  GPIO_InitStruct.Pin = MULT_IN_Z_Pin|GPIO_PIN_12;
  GPIO_InitStruct.Mode = GPIO_MODE_OUTPUT_PP;
  GPIO_InitStruct.Pull = GPIO_NOPULL;
  GPIO_InitStruct.Speed = GPIO_SPEED_FREQ_LOW;
  HAL_GPIO_Init(GPIOB, &GPIO_InitStruct);

  /*Configure GPIO pin : PD7 */
  GPIO_InitStruct.Pin = GPIO_PIN_7;
  GPIO_InitStruct.Mode = GPIO_MODE_INPUT;
  GPIO_InitStruct.Pull = GPIO_NOPULL;
  HAL_GPIO_Init(GPIOD, &GPIO_InitStruct);

  /*Configure GPIO pins : PG10 USB_C_Reset_Pin USB_C_Alert_Pin */
  GPIO_InitStruct.Pin = GPIO_PIN_10|USB_C_Reset_Pin|USB_C_Alert_Pin;
  GPIO_InitStruct.Mode = GPIO_MODE_OUTPUT_PP;
  GPIO_InitStruct.Pull = GPIO_NOPULL;
  GPIO_InitStruct.Speed = GPIO_SPEED_FREQ_LOW;
  HAL_GPIO_Init(GPIOG, &GPIO_InitStruct);

}

/* USER CODE BEGIN 4 */
// TODO:
void HAL_GPIO_EXTI_Callback(uint16_t GPIO_Pin){

  //SPI1 MISO
  if (GPIO_Pin == GPIO_PIN_6){
    HAL_NVIC_DisableIRQ(EXTI9_5_IRQn);
    HAL_SPI_TransmitReceive_DMA(&hspi1, pTxData, spi1Buffer, 4);
  }

  //SPI2 MISO
  else if (GPIO_Pin == GPIO_PIN_14){
    HAL_NVIC_DisableIRQ(EXTI15_10_IRQn);
    HAL_SPI_TransmitReceive_DMA(&hspi2, pTxData, spi2Buffer, 4);
  }
  //SPI4 MISO
  else if (GPIO_Pin == GPIO_PIN_5){
    HAL_NVIC_DisableIRQ(EXTI9_5_IRQn);
    HAL_SPI_TransmitReceive_DMA(&hspi4, pTxData, spi4Buffer, 4);
   }

  // buttons
  else if (GPIO_Pin == GPIO_PIN_7){
    if(sdCardWriteEnable == false){
      sdCardOpenFileError = sd_card_open_file();
      if (sdCardOpenFileError == true){
        setColorLED(red);
      }else{
        sdCardWriteEnable = true;
      }
    }else{
      sdCardWriteEnable = false;
      sd_card_close_file();
      setColorLED(blue);
    }

  }
  else if (GPIO_Pin == GPIO_PIN_9){
    __NOP();
    //sendToSDcard = true;
  }
}

//FIXME: changed here from TxRx to Rx
void HAL_SPI_TxRxCpltCallback(SPI_HandleTypeDef *hspi)
{
  if (hspi == &hspi1){
    spi1ValuesStorage[spi1ValuesBufferCounter] = (uint32_t)spi1Buffer[3] | ((uint32_t)spi1Buffer[2] << 8) | ((uint32_t)spi1Buffer[1] << 16) | ((uint32_t)spi1Buffer[0] << 24);;
    __HAL_GPIO_EXTI_CLEAR_IT(GPIO_PIN_6);
    HAL_NVIC_EnableIRQ(EXTI9_5_IRQn);
    spi1ValuesBufferCounter++;
  }

  if (hspi == &hspi2){
    spi2ValuesStorage[spi2ValuesBufferCounter] = (uint32_t)spi2Buffer[3] | ((uint32_t)spi2Buffer[2] << 8) | ((uint32_t)spi2Buffer[1] << 16) | ((uint32_t)spi2Buffer[0] << 24);
    __HAL_GPIO_EXTI_CLEAR_IT(GPIO_PIN_14);
    HAL_NVIC_EnableIRQ(EXTI15_10_IRQn);
    spi2ValuesBufferCounter++;
  }

  if (hspi == &hspi4){
    spi4ValuesStorage[spi4ValuesBufferCounter] = (uint32_t)spi4Buffer[3] | ((uint32_t)spi4Buffer[2] << 8) | ((uint32_t)spi4Buffer[1] << 16) | ((uint32_t)spi4Buffer[0] << 24);
    __HAL_GPIO_EXTI_CLEAR_IT(GPIO_PIN_5);
    HAL_NVIC_EnableIRQ(EXTI9_5_IRQn);
    spi4ValuesBufferCounter++;
  }
}

void HAL_UART_RxCpltCallback(UART_HandleTypeDef *huart)
{
  if (huart == &huart4){
    HAL_UART_Receive_IT (&huart4, rxUart4Buffer, 1);
    uartCommand = rxUart4Buffer[0];
    uartNewCommand = true;

  }
  else if (huart == &huart5){
      HAL_UART_Receive_IT (&huart5, rxUart5Buffer, 1);
      uartCommand = rxUart5Buffer[0];
      uartNewCommand = true;
  }
}

void HAL_TIM_PeriodElapsedCallback(TIM_HandleTypeDef *htim){
  if(htim == &htim16){
    HAL_GPIO_TogglePin(GPIOA, GPIO_PIN_12);
  }
}

uint32_t findMin(uint32_t a, uint32_t b, uint32_t c) {
    uint32_t min = a;
    if (b < min) {
        min = b;
    }
    if (c < min) {
        min = c;
    }
    return min;
}

void setColorLED(colorLED color){
  if(color == red){
    HAL_GPIO_WritePin(GPIOA, GPIO_PIN_9, GPIO_PIN_SET);
    HAL_GPIO_WritePin(GPIOA, GPIO_PIN_10, GPIO_PIN_RESET);
    HAL_GPIO_WritePin(GPIOA, GPIO_PIN_11, GPIO_PIN_RESET);
  }else if(color == blue){
    HAL_GPIO_WritePin(GPIOA, GPIO_PIN_9, GPIO_PIN_RESET);
    HAL_GPIO_WritePin(GPIOA, GPIO_PIN_10, GPIO_PIN_SET);
    HAL_GPIO_WritePin(GPIOA, GPIO_PIN_11, GPIO_PIN_RESET);
  } else if (color == green){
    HAL_GPIO_WritePin(GPIOA, GPIO_PIN_9, GPIO_PIN_RESET);
    HAL_GPIO_WritePin(GPIOA, GPIO_PIN_10, GPIO_PIN_RESET);
    HAL_GPIO_WritePin(GPIOA, GPIO_PIN_11, GPIO_PIN_SET);
  }
}

void readConfigFile(const char* filename) {
  uint8_t bufferSize =128;
  FRESULT result;
  char buffer[bufferSize];

  // Open the file
  result = f_open(&SDFile, filename, FA_READ);
  if (result != FR_OK) {
      // Handle file open error
  }

  // Read and parse each line
  while (f_gets(buffer, sizeof(buffer), &SDFile) != NULL) {
      // Split the line into key and value
      char* key = strtok(buffer, ": ");
      char* value = strtok(NULL, ": ");

      // Handle each key-value pair
      if (strcmp(key, "range_x") == 0) {
        // Save value for range_x
        range_x_value = value[0];
      } else if (strcmp(key, "range_y") == 0) {
        // Save value for range_y
        range_y_value = value[0];
      } else if (strcmp(key, "range_z") == 0) {
        // Save value for range_z
        range_z_value = value[0];
      } else if (strcmp(key, "sps") == 0) {
        // Save value for sps
        sps = atoi(value);
      } else if (strcmp(key, "floating_point_values") == 0) {
        // Save value for floating_point_values
        floating_point_values = atoi(value) != 0;
      } else if (strcmp(key, "saving_to_sd_card") == 0) {
        // Save value for saving_to_sd_card
        saving_to_sd_card =  atoi(value) != 0;
      } else if (strcmp(key, "gain_x") == 0) {
        // Save value for gain_x
        gain_x = atof(value);
      } else if (strcmp(key, "gain_y") == 0) {
        // Save value for gain_y
        gain_y = atof(value);
      } else if (strcmp(key, "gain_z") == 0) {
        // Save value for gain_z
        gain_z = atof(value);
      } else if (strcmp(key, "offset_x") == 0) {
        // Save value for offset_x
        offset_x = atoi(value);
      } else if (strcmp(key, "offset_y") == 0) {
        // Save value for offset_y
        offset_y = atoi(value);
      } else if (strcmp(key, "offset_z") == 0) {
        // Save value for offset_z
        offset_z = atoi(value);
      }
      // Add more key comparisons as needed

      // Clear buffer for the next line
      memset(buffer, 0, sizeof(buffer));
  }

  // Close the file
  f_close(&SDFile);
}

void initialSetupADC(void){
  if(range_x_value == 'H'){
    HAL_GPIO_WritePin(GPIOA, GPIO_PIN_5, GPIO_PIN_RESET);
  }else{
    HAL_GPIO_WritePin(GPIOA, GPIO_PIN_5, GPIO_PIN_SET);
  }
  if(range_y_value == 'H'){
    HAL_GPIO_WritePin(GPIOC, GPIO_PIN_4, GPIO_PIN_RESET);
  }else{
    HAL_GPIO_WritePin(GPIOC, GPIO_PIN_4, GPIO_PIN_SET);
  }
  if(range_y_value == 'H'){
    HAL_GPIO_WritePin(GPIOB, GPIO_PIN_0, GPIO_PIN_RESET);
  }else{
    HAL_GPIO_WritePin(GPIOB, GPIO_PIN_0, GPIO_PIN_SET);
  }

  spi1_soft_reset();
  spi2_soft_reset();
  spi4_soft_reset();
  uint8_t spsHex = SPS_VALUE_5;
  if (sps == 5){
    spsHex = SPS_VALUE_5;
  }else if(sps == 20){
    spsHex = SPS_VALUE_20;
  }else if(sps == 100){
    spsHex = SPS_VALUE_100;
  }else if(sps == 500){
    spsHex = SPS_VALUE_500;
  }else if(sps == 1000){
    spsHex = SPS_VALUE_1000;
  }

  spi1_adc_init(spsHex);
  spi2_adc_init(spsHex);
  spi4_adc_init(spsHex);

}

void print_help_uart(void){
  char message[] = "Napoveda pro ovladani modulu:\r\n"
                   "a - rozsah +-10V pro kanal X\r\n"
                   "b - rozsah +-0.5V pro kanal X\r\n"
                   "c - rozsah +-10V pro kanal Y\r\n"
                   "d - rozsah +-0.5V pro kanal Y\r\n"
                   "e - rozsah +-10V pro kanal Z\r\n"
                   "f - rozsah +-0.5V pro kanal Z\r\n"
                   "p - zapnuti vypisovani desetinnych cisel\r\n"
                   "r - zapnuti vypisovani 32bit cisel\r\n"
                   "s - zapnuti odesilani dat\r\n"
                   "s - vypnuti odesilani dat\r\n"
                   "h,? - napoveda\r\n"
                   "0 - nastaveni SPS na 5\r\n"
                   "1 - nastaveni SPS na 20\r\n"
                   "2 - nastaveni SPS na 100\r\n"
                   "3 - nastaveni SPS na 500\r\n"
                   "4 - nastaveni SPS na 1000\r\n";

  HAL_UART_Transmit(&huart4, message, strlen(message),100);
  HAL_UART_Transmit(&huart5, message, strlen(message),100);

}
/* USER CODE END 4 */

void Error_Handler(void)
{
  __disable_irq();
  while (1)
  {
  }
}
